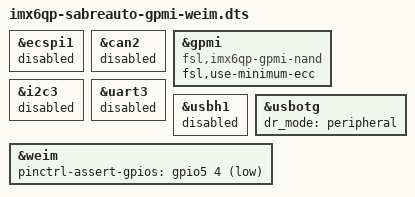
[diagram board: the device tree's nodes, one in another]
// SPDX-License-Identifier: GPL-2.0
//
// Copyright (C) 2015 Freescale Semiconductor, Inc.

#include "imx6qp-sabreauto.dts"

&ecspi1 {
	/* pin conflict with weim */
	status = "disabled";
};

&can2 {
	/* max7310_c on i2c3 is gone */
	status = "disabled";
};

&gpmi {
	compatible = "fsl,imx6qp-gpmi-nand";
	fsl,use-minimum-ecc;
	status = "okay";
};

&i2c3 {
	/* pin conflict with weim */
	status = "disabled";
};

&uart3 {
	/* pin conflict with gpmi and weim */
	status = "disabled";
};

&usbh1 {
	/* max7310_b on i2c3 is gone */
	status = "disabled";
};

&usbotg {
	/* max7310_c on i2c3 is gone */
	status = "okay";
	dr_mode = "peripheral";
};

&weim {
	pinctrl-assert-gpios = <&gpio5 4 GPIO_ACTIVE_LOW>;
	status = "okay";
};
